AUTOSAR XML (schema 4-3-0)
package /BMW/Platform/Dlog/SwcImplementations
  swc implementation DlogImpl: behavior=Internal_Dlog
    code-descriptors:
      code Code: artifact-descriptors=autosar-engineering-object={short-label=Default, category=SWSRC}
package /BMW/Platform/Dlog/SwComponentTypes
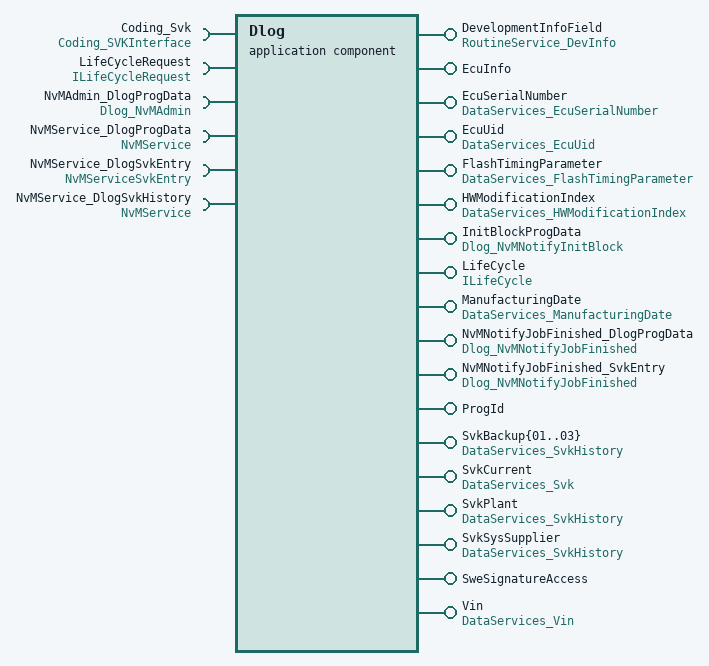
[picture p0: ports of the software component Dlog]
  application sw component type Dlog
    20 x provide port:
      DevelopmentInfoField: server-com-spec{operation=Start, queue-length=1}, provided-interface=RoutineService_DevInfo
      EcuInfo: provided-com-specs=[{operation=GetEcuId, queue-length=1}, {operation=GetVin, queue-length=1}], provided-interface=EcuInfo
      EcuSerialNumber: server-com-spec{operation=ReadData, queue-length=1}, provided-interface=DataServices_EcuSerialNumber
      EcuUid: server-com-spec{operation=ReadData, queue-length=1}, provided-interface=DataServices_EcuUid
      FlashTimingParameter: server-com-spec{operation=ReadData, queue-length=1}, provided-interface=DataServices_FlashTimingParameter
      HWModificationIndex: server-com-spec{operation=ReadData, queue-length=1}, provided-interface=DataServices_HWModificationIndex
      InitBlockProgData: server-com-spec{operation=InitBlock, queue-length=1}, provided-interface=Dlog_NvMNotifyInitBlock
      LifeCycle: mode-switch-sender-com-spec{enhanced-mode-api=true, mode-group=Mode, mode-switched-ack=timeout=0, queue-length=2}, provided-interface=ILifeCycle
      ManufacturingDate: server-com-spec{operation=ReadData, queue-length=1}, provided-interface=DataServices_ManufacturingDate
      NvMNotifyJobFinished_DlogProgData: server-com-spec{operation=JobFinished, queue-length=1}, provided-interface=Dlog_NvMNotifyJobFinished
      NvMNotifyJobFinished_SvkEntry: server-com-spec{operation=JobFinished, queue-length=1}, provided-interface=Dlog_NvMNotifyJobFinished
      ProgId: nonqueued-sender-com-spec{data-element=progId, init-value=8 x 0}, provided-interface=ProgId
      SvkBackup{01..03}: provided-com-specs=[{operation=ConditionCheckRead, queue-length=1}, {operation=ReadData, queue-length=1}], provided-interface=DataServices_SvkHistory
      SvkCurrent: provided-interface=DataServices_Svk
        provided-com-specs:
          operation=ConditionCheckRead, queue-length=1
          operation=ReadData, queue-length=1
          operation=ReadDataLength, queue-length=1
      SvkPlant: provided-com-specs=[{operation=ConditionCheckRead, queue-length=1}, {operation=ReadData, queue-length=1}], provided-interface=DataServices_SvkHistory
      SvkSysSupplier: provided-com-specs=[{operation=ConditionCheckRead, queue-length=1}, {operation=ReadData, queue-length=1}], provided-interface=DataServices_SvkHistory
      SweSignatureAccess: provided-interface=SweSignatureAccess
        provided-com-specs:
          operation=GetNumSig, queue-length=1
          operation=GetNumSwe, queue-length=1
          operation=GetSigLength, queue-length=1
          operation=GetSignature, queue-length=1
          operation=GetSigStart, queue-length=1
      Vin: provided-com-specs=[{operation=ConditionCheckRead, queue-length=1}, {operation=ReadData, queue-length=1}], provided-interface=DataServices_Vin
    6 x require port:
      Coding_Svk: required-interface=Coding_SVKInterface
      LifeCycleRequest: nonqueued-receiver-com-spec{data-element=requestMode, filter=data-filter-type=ALWAYS, init-value=2}, required-interface=ILifeCycleRequest
      NvMAdmin_DlogProgData: required-interface=Dlog_NvMAdmin
      NvMService_DlogProgData: required-interface=NvMService
      NvMService_DlogSvkEntry: required-interface=NvMServiceSvkEntry
      NvMService_DlogSvkHistory: required-interface=NvMService
    behavior Internal_Dlog: data-type-mapping=DlogTypeMappings
      10 x operation invoked event:
        OIEventCCSvkBackup{01..03}: start-on-event=CondCheckSvkBackup{01..03}, operation=SvkBackup{01..03}.ConditionCheckRead
        OIEventCCSvkCurrent: start-on-event=CondCheckSvkCurrent, operation=SvkCurrent.ConditionCheckRead
        OIEventCCSvkPlant: start-on-event=CondCheckSvkPlant, operation=SvkPlant.ConditionCheckRead
        OIEventCCSvkSystemSupplier: start-on-event=CondCheckSvkSysSupplier, operation=SvkSysSupplier.ConditionCheckRead
        oie_Vin_ConditionCheckRead: start-on-event=CondCheckVin, operation=Vin.ConditionCheckRead
        OIEventDataLengthSvkCurrent: start-on-event=DataLengthSvkCurrent, operation=SvkCurrent.ReadDataLength
        oie_EcuInfo_GetEcuId: start-on-event=Dlog_GetEcuId, operation=EcuInfo.GetEcuId
        oie_EcuInfo_GetVin: start-on-event=Dlog_GetVin, operation=EcuInfo.GetVin
      mode switched ack event LifeCycleModeSwitchedAck: start-on-event=Dlog_ModeSwitchAckLifeCycle, event-source=Dlog_ModeSwitchAckLifeCycle/mspDlogModeSwitch
      data received event LifeCycleRequest: start-on-event=Dlog_ModeSwitchRequestLifeCycle, data=LifeCycleRequest.requestMode
      21 x operation invoked event:
        oie_NvMNotifyJobFinished_DlogProgData_JobFinished: start-on-event=Dlog_NotifyJobFinishedProgData, operation=NvMNotifyJobFinished_DlogProgData.JobFinished
        oie_NvMNotifyJobFinished_SvkEntry_JobFinished: start-on-event=Dlog_NotifyJobFinishedSvkEntry, operation=NvMNotifyJobFinished_SvkEntry.JobFinished
        oie_EcuUid_ReadData: start-on-event=Dlog_ReadDataByIdentifierEcuUid, operation=EcuUid.ReadData
        oie_HWModificationIndex_ReadData: start-on-event=Dlog_ReadDataByIdentifierHWModificationIndex, operation=HWModificationIndex.ReadData
        oie_InitBlockProgData_InitBlock: start-on-event=InitBlockProgData, operation=InitBlockProgData.InitBlock
        OIEventReadEcuSerialNumber: start-on-event=ReadEcuSerialNumber, operation=EcuSerialNumber.ReadData
        OIEventReadTimingParameters: start-on-event=ReadFlashTimingParameter, operation=FlashTimingParameter.ReadData
        OIEventReadManufacturingData: start-on-event=ReadManufacturingDate, operation=ManufacturingDate.ReadData
        OIEventReadSvkBackup{01..03}: start-on-event=ReadSvkBackup{01..03}, operation=SvkBackup{01..03}.ReadData
        OIEventReadSvkCurrent: start-on-event=ReadSvkCurrent, operation=SvkCurrent.ReadData
        OIEventReadSvkPlant: start-on-event=ReadSvkPlant, operation=SvkPlant.ReadData
        OIEventReadSvkSystemSupplier: start-on-event=ReadSvkSysSupplier, operation=SvkSysSupplier.ReadData
        OIEventReadVin: start-on-event=ReadVin, operation=Vin.ReadData
        OIEventStartReadDevInfoField: start-on-event=StartReadReadDevInfoField, operation=DevelopmentInfoField.Start
        oie_SweSignatureAccess_GetNumSig: start-on-event=SweGetNumSig, operation=SweSignatureAccess.GetNumSig
        oie_SweSignatureAccess_GetNumSwe: start-on-event=SweGetNumSwe, operation=SweSignatureAccess.GetNumSwe
        oie_SweSignatureAccess_SweGetSigLength: start-on-event=SweGetSigLength, operation=SweSignatureAccess.GetSigLength
        oie_SweSignatureAccess_SweGetSignature: start-on-event=SweGetSignature, operation=SweSignatureAccess.GetSignature
        oie_SweSignatureAccess_GetSigStart: start-on-event=SweGetSigStart, operation=SweSignatureAccess.GetSigStart
      33 x runnable:
        CondCheckSvkBackup01: symbol=Dlog_ConditionCheckSvkBackup01
          sync call scp_ReadBlock: operation=NvMService_DlogSvkEntry.ReadBlock, timeout=0
          sync call scp_SetDataIndex: operation=NvMService_DlogSvkEntry.SetDataIndex, timeout=0
        CondCheckSvkBackup02: symbol=Dlog_ConditionCheckSvkBackup02
          sync call scp_ReadBlock: operation=NvMService_DlogSvkEntry.ReadBlock, timeout=0
          sync call scp_SetDataIndex: operation=NvMService_DlogSvkEntry.SetDataIndex, timeout=0
        CondCheckSvkBackup03: symbol=Dlog_ConditionCheckSvkBackup03
          sync call scp_ReadBlock: operation=NvMService_DlogSvkEntry.ReadBlock, timeout=0
          sync call scp_SetDataIndex: operation=NvMService_DlogSvkEntry.SetDataIndex, timeout=0
        CondCheckSvkCurrent: symbol=Dlog_ConditionCheckSvkCurrent
          sync call scp_GetCafIds: operation=Coding_Svk.GetCafIds, timeout=0
        CondCheckSvkPlant: symbol=Dlog_ConditionCheckSvkPlant
          sync call scp_ReadBlock: operation=NvMService_DlogSvkEntry.ReadBlock, timeout=0
          sync call scp_SetDataIndex: operation=NvMService_DlogSvkEntry.SetDataIndex, timeout=0
        CondCheckSvkSysSupplier: symbol=Dlog_ConditionCheckSvkSysSupplier
          sync call scp_ReadBlock: operation=NvMService_DlogSvkEntry.ReadBlock, timeout=0
          sync call scp_SetDataIndex: operation=NvMService_DlogSvkEntry.SetDataIndex, timeout=0
        CondCheckVin: symbol=Dlog_ConditionCheckVin
        DataLengthSvkCurrent: symbol=Dlog_ReadDataLengthSvkCurrent
        Dlog_GetEcuId: can-be-invoked-concurrently=true
        Dlog_GetVin: can-be-invoked-concurrently=true
        Dlog_ModeSwitchAckLifeCycle
          data-send-points:
            access dsp_progId: accessed-variable=ProgId.progId
          mode switch point mspDlogModeSwitch: mode-group=LifeCycle.Mode
        Dlog_ModeSwitchRequestLifeCycle: mode-access-point=LifeCycle.Mode
          data-read-access:
            access dra_requestedMode: accessed-variable=LifeCycleRequest.requestMode
          data-send-points:
            access dsp_progId: accessed-variable=ProgId.progId
          mode switch point mspDlogModeSwitch: mode-group=LifeCycle.Mode
          4 x sync call, all with timeout=0:
            scp_GetErrorStatus: operation=NvMService_DlogSvkHistory.GetErrorStatus
            scp_WriteBlock: operation=NvMService_DlogSvkEntry.WriteBlock
            scp_WriteBlock1: operation=NvMService_DlogProgData.WriteBlock
            scp_WriteBlock2: operation=NvMService_DlogSvkHistory.WriteBlock
        Dlog_NotifyJobFinishedProgData
          sync call scp_SetBlockProtection: operation=NvMAdmin_DlogProgData.SetBlockProtection, timeout=0
        Dlog_NotifyJobFinishedSvkEntry
        Dlog_ReadDataByIdentifierEcuUid
        Dlog_ReadDataByIdentifierHWModificationIndex
        InitBlockProgData: symbol=Dlog_InitProgData
        ReadEcuSerialNumber: symbol=Dlog_ReadDataByIdentifierEcuSerialNumber
        ReadFlashTimingParameter: symbol=Dlog_ReadDataByIdentifierFlashTimingParameter
        ReadManufacturingDate: symbol=Dlog_ReadDataByIdentifierManufacturingDate
        ReadSvkBackup{01..03}: symbol=Dlog_ReadDataByIdentifierSvkBackup{01..03}
        ReadSvkCurrent: symbol=Dlog_ReadDataByIdentifierSvkCurrent
        ReadSvkPlant: symbol=Dlog_ReadDataByIdentifierSvkPlant
        ReadSvkSysSupplier: symbol=Dlog_ReadDataByIdentifierSvkSysSupplier
        ReadVin: symbol=Dlog_ReadDataByIdentifierVin
        StartReadReadDevInfoField: symbol=Dlog_RoutineControlStartReadDevelopmentInfoField
        SweGetNumSig: can-be-invoked-concurrently=true, symbol=Dlog_SweGetNumSig
        SweGetNumSwe: can-be-invoked-concurrently=true, symbol=Dlog_SweGetNumSwe
        SweGetSigLength: can-be-invoked-concurrently=true, symbol=Dlog_SweGetSigLength
        SweGetSignature: can-be-invoked-concurrently=true, symbol=Dlog_SweGetSignatureRte
        SweGetSigStart: can-be-invoked-concurrently=true, symbol=Dlog_SweGetSigStart
      14 x swc service dependency:
        SD_NVB_ProgData
          assigned-ports:
            port-prototype=InitBlockProgData, role=NvMNotifyInitBlock
            port-prototype=NvMService_DlogProgData, role=NvMService
            port-prototype=NvMAdmin_DlogProgData, role=NvMAdmin
          service-needs:
            nv block needs sn_SD_NVB_ProgData: resistant-to-changed-sw=false, restore-at-start=true, store-at-shutdown=true
        SD_NVB_SvkEntry
          assigned-ports:
            port-prototype=NvMNotifyJobFinished_SvkEntry, role=NvMNotifyJobFinished
            port-prototype=NvMService_DlogSvkEntry, role=NvMService
          service-needs:
            nv block needs sn_SD_NVB_SvkEntry: n-data-sets=5, readonly=false, resistant-to-changed-sw=true, restore-at-start=false
        SD_NVB_SvkHistory
          service-needs:
            nv block needs sn_SD_NVB_SvkHistory: readonly=true, resistant-to-changed-sw=true, restore-at-start=true
        SD_Dcm_DS_EcuSerialNumber: assigned-ports=role-based-port-assignment={port-prototype=EcuSerialNumber, role=DataServices}
          service-needs:
            diagnostic value needs sn_SD_Dcm_DS_EcuSerialNumber: did-number=61836
        SD_Dcm_DS_ManufacturingData: assigned-ports=role-based-port-assignment={port-prototype=ManufacturingDate, role=DataServices}
          service-needs:
            diagnostic value needs sn_SD_Dcm_DS_ManufacturingData: did-number=61835
        SD_Dcm_DS_SvkBackup01: assigned-ports=role-based-port-assignment={port-prototype=SvkBackup01, role=DataServices}
          service-needs:
            diagnostic value needs sn_SD_Dcm_DS_SvkBackup01: did-number=61700
        SD_Dcm_DS_SvkBackup02: assigned-ports=role-based-port-assignment={port-prototype=SvkBackup02, role=DataServices}
          service-needs:
            diagnostic value needs sn_SD_Dcm_DS_SvkBackup02: did-number=61701
        SD_Dcm_DS_SvkBackup03: assigned-ports=role-based-port-assignment={port-prototype=SvkBackup03, role=DataServices}
          service-needs:
            diagnostic value needs sn_SD_Dcm_DS_SvkBackup03: did-number=61702
        SD_Dcm_DS_SvkCurrent: assigned-ports=role-based-port-assignment={port-prototype=SvkCurrent, role=DataServices}
          service-needs:
            diagnostic value needs sn_SD_Rdbi_SvkCurrent: did-number=61697
        SD_Dcm_DS_SvkPlant: assigned-ports=role-based-port-assignment={port-prototype=SvkPlant, role=DataServices}
          service-needs:
            diagnostic value needs sn_SD_Dcm_DS_SvkPlant: did-number=61699
        SD_Dcm_DS_SvkSystemSupplier: assigned-ports=role-based-port-assignment={port-prototype=SvkSysSupplier, role=DataServices}
          service-needs:
            diagnostic value needs sn_SD_Dcm_DS_SvkSystemSupplier: did-number=61698
        SD_Dcm_DS_TimingParameters: assigned-ports=role-based-port-assignment={port-prototype=FlashTimingParameter, role=DataServices}
          service-needs:
            diagnostic value needs sn_SD_Dcm_DS_TimingParameters: did-number=9476
        SD_Dcm_DS_Vin: assigned-ports=role-based-port-assignment={port-prototype=Vin, role=DataServices}
          service-needs:
            diagnostic value needs sn_SD_Dcm_DS_Vin: did-number=61840
        SD_Dcm_RS_DevelopmentInfoField: assigned-ports=role-based-port-assignment={port-prototype=DevelopmentInfoField, role=RoutineServices}
          service-needs:
            diagnostic routine needs sn_SD_Dcm_RS_DevelopmentInfoField: diag-routine-type=SYNCHRONOUS, rid-number=517
